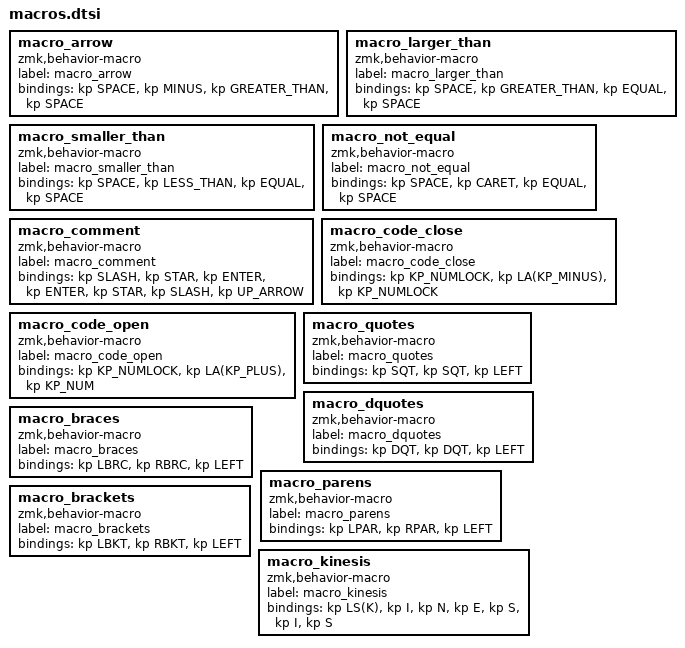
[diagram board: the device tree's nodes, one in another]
macro_arrow: macro_arrow{
compatible = "zmk,behavior-macro";
label = "macro_arrow";
#binding-cells = <0>;
bindings = <&kp SPACE>, <&kp MINUS>, <&kp GREATER_THAN>, <&kp SPACE>;
};
macro_larger_than: macro_larger_than{
compatible = "zmk,behavior-macro";
label = "macro_larger_than";
#binding-cells = <0>;
bindings = <&kp SPACE>, <&kp GREATER_THAN>, <&kp EQUAL>, <&kp SPACE>;
};
macro_smaller_than: macro_smaller_than{
compatible = "zmk,behavior-macro";
label = "macro_smaller_than";
#binding-cells = <0>;
bindings = <&kp SPACE>, <&kp LESS_THAN>, <&kp EQUAL>, <&kp SPACE>;
};
macro_not_equal: macro_not_equal{
compatible = "zmk,behavior-macro";
label = "macro_not_equal";
#binding-cells = <0>;
bindings = <&kp SPACE>, <&kp CARET>, <&kp EQUAL>, <&kp SPACE>;
};
macro_comment: macro_comment{
compatible = "zmk,behavior-macro";
label = "macro_comment";
#binding-cells = <0>;
bindings = <&kp SLASH>, <&kp STAR>, <&kp ENTER>, <&kp ENTER>, <&kp STAR>, <&kp SLASH>, <&kp UP_ARROW>;
};
macro_code_close: macro_code_close{
compatible = "zmk,behavior-macro";
label = "macro_code_close";
#binding-cells = <0>;
bindings = <&kp KP_NUMLOCK>, <&kp LA(KP_MINUS)>, <&kp KP_NUMLOCK>;
};
macro_code_open: macro_code_open{
compatible = "zmk,behavior-macro";
label = "macro_code_open";
#binding-cells = <0>;
bindings = <&kp KP_NUMLOCK>, <&kp LA(KP_PLUS)>, <&kp KP_NUM>;
};
macro_quotes: macro_quotes{
compatible = "zmk,behavior-macro";
label = "macro_quotes";
#binding-cells = <0>;
bindings = <&kp SQT>, <&kp SQT>, <&kp LEFT>;
};
macro_dquotes: macro_dquotes{
compatible = "zmk,behavior-macro";
label = "macro_dquotes";
#binding-cells = <0>;
bindings = <&kp DQT>, <&kp DQT>, <&kp LEFT>;
};
macro_braces: macro_braces{
compatible = "zmk,behavior-macro";
label = "macro_braces";
#binding-cells = <0>;
bindings = <&kp LBRC>, <&kp RBRC>, <&kp LEFT>;
};
macro_parens: macro_parens{
compatible = "zmk,behavior-macro";
label = "macro_parens";
#binding-cells = <0>;
bindings = <&kp LPAR>, <&kp RPAR>, <&kp LEFT>;
};
macro_brackets: macro_brackets{
compatible = "zmk,behavior-macro";
label = "macro_brackets";
#binding-cells = <0>;
bindings = <&kp LBKT>, <&kp RBKT>, <&kp LEFT>;
};
macro_kinesis: macro_kinesis{
compatible = "zmk,behavior-macro";
label = "macro_kinesis";
#binding-cells = <0>;
bindings = <&kp LS(K)>, <&kp I>, <&kp N>, <&kp E>, <&kp S>, <&kp I>, <&kp S>;
};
